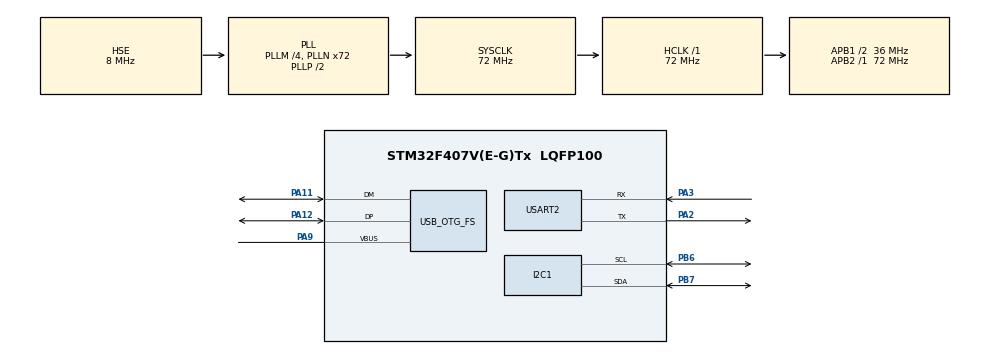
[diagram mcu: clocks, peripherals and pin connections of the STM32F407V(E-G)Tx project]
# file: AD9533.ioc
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Mcu.Family=STM32F4
Mcu.Name=STM32F407V(E-G)Tx
Mcu.Package=LQFP100
NVIC.I2C1_ER_IRQn=true\:2\:0\:true\:false\:true\:true\:true\:true
NVIC.I2C1_EV_IRQn=true\:2\:0\:true\:false\:true\:true\:true\:true
NVIC.OTG_FS_IRQn=true\:0\:0\:false\:false\:true\:false\:true\:true
NVIC.PriorityGroup=NVIC_PRIORITYGROUP_2
PA11.Mode=Device_Only
PA11.Signal=USB_OTG_FS_DM
PA12.Mode=Device_Only
PA12.Signal=USB_OTG_FS_DP
PA2.Mode=Asynchronous
PA2.Signal=USART2_TX
PA3.Mode=Asynchronous
PA3.Signal=USART2_RX
PA9.Mode=Activate_VBUS
PA9.Signal=USB_OTG_FS_VBUS
PB6.Mode=I2C
PB6.Signal=I2C1_SCL
PB7.Mode=I2C
PB7.Signal=I2C1_SDA
PH0-OSC_IN.Mode=HSE-External-Oscillator
PH0-OSC_IN.Signal=RCC_OSC_IN
PH1-OSC_OUT.Mode=HSE-External-Oscillator
PH1-OSC_OUT.Signal=RCC_OSC_OUT
ProjectManager.HeapSize=0x200
ProjectManager.StackSize=0x400
ProjectManager.TargetToolchain=STM32CubeIDE
RCC.48MHZClocksFreq_Value=48000000
RCC.AHBFreq_Value=72000000
RCC.APB1CLKDivider=RCC_HCLK_DIV2
RCC.APB1Freq_Value=36000000
RCC.APB1TimFreq_Value=72000000
RCC.APB2Freq_Value=72000000
RCC.APB2TimFreq_Value=72000000
RCC.CortexFreq_Value=72000000
RCC.HCLKFreq_Value=72000000
RCC.HSE_VALUE=8000000
RCC.HSI_VALUE=16000000
RCC.LSE_VALUE=32768
RCC.PLLM=4
RCC.PLLN=72
RCC.PLLQ=3
RCC.SYSCLKFreq_VALUE=72000000
RCC.SYSCLKSource=RCC_SYSCLKSOURCE_PLLCLK
RCC.VCOOutputFreq_Value=144000000
USART2.VirtualMode=VM_ASYNC
USB_DEVICE.CLASS_NAME_FS=CDC
USB_DEVICE.VirtualMode-CDC_FS=Cdc
USB_DEVICE.VirtualModeFS=Cdc_FS
USB_OTG_FS.VirtualMode=Device_Only
VP_USB_DEVICE_VS_USB_DEVICE_CDC_FS.Mode=CDC_FS
board=custom

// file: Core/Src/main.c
/* USER CODE BEGIN Header */
/**
  ******************************************************************************
  * @file           : main.c
  * @brief          : Main program body
  ******************************************************************************
  * @attention
  *
  * Copyright (c) 2022 STMicroelectronics.
  * All rights reserved.
  *
  * This software is licensed under terms that can be found in the LICENSE file
  * in the root directory of this software component.
  * If no LICENSE file comes with this software, it is provided AS-IS.
  *
  ******************************************************************************
  */
/* USER CODE END Header */
#include "main.h"
#include "usb_device.h"

/* USER CODE BEGIN Includes */
#include "usbd_cdc_if.h"
#include <string.h>
#include "AD5933.h"

/* USER CODE END Includes */

I2C_HandleTypeDef hi2c1;

UART_HandleTypeDef huart2;

void SystemClock_Config(void);
static void MX_GPIO_Init(void);
static void MX_I2C1_Init(void);
static void MX_USART2_UART_Init(void);
void dmsg(char *msg);

int main(void)
{
  /* USER CODE BEGIN 1 */
	ad5933_t dev1={0};
	float temp=0;
	char msg[100]={0};
	int16_t real=0, imag=0;
  /* USER CODE END 1 */

  /* MCU Configuration--------------------------------------------------------*/

  /* Reset of all peripherals, Initializes the Flash interface and the Systick. */
  HAL_Init();

  /* Configure the system clock */
  SystemClock_Config();

  /* Initialize all configured peripherals */
  MX_GPIO_Init();
  MX_I2C1_Init();
  MX_USART2_UART_Init();
  MX_USB_DEVICE_Init();
  /* USER CODE BEGIN 2 */

  ad5933_init(&dev1, &hi2c1, 16000000, AD5933_CONTROL_EXT_SYSCLK , AD5933_GAIN_X1, AD5933_RANGE_2000mVpp);
  ad5933_configSweep(&dev1, 30000, 10, 10);
  ad5933_setSettlingTime(&dev1, AD5933_SETTLING_X1, 15);
  ad5933_startSweep(&dev1);
  /* USER CODE END 2 */

  /* Infinite loop */
  while (1)
  {
//	  temp = ad5933_getTemperature(&dev1);
//	  memset(msg,0,sizeof(msg));
//	  sprintf(msg,"Temp: %.2f",temp);
//	  dmsg(msg);
//	  memset(msg,0,sizeof(msg));
//	  sprintf(msg,"start: %lx",ad5933_getReg(&dev1, AD5933_REG_FREQ_START, 3));
//	  dmsg(msg);
//	  memset(msg,0,sizeof(msg));
//	  sprintf(msg,"inc: %lx",ad5933_getReg(&dev1, AD5933_REG_FREQ_INC, 3));
//	  dmsg(msg);
//	  memset(msg,0,sizeof(msg));
//	  sprintf(msg,"num: %lx",ad5933_getReg(&dev1, AD5933_REG_INC_NUM, 2));
//	  dmsg(msg);
//	  memset(msg,0,sizeof(msg));
//	  sprintf(msg,"num: %lx",ad5933_getReg(&dev1,AD5933_REG_SETTLING_CYCLES, 2));
//	  dmsg(msg);

	  ad5933_repeatFreq(&dev1, &imag, &real);
	  memset(msg,0,sizeof(msg));
	  sprintf(msg,"%d %d", real, imag);
	  dmsg(msg);

	  HAL_Delay (10);
  }

}

void dmsg(char *msg)
{
	char *str = malloc(strlen(msg) + 3);
	strcpy(str, msg);
	strcat(str, "\r\n");
	CDC_Transmit_FS((uint8_t*)str, strlen(str));
}

void SystemClock_Config(void)
{
  RCC_OscInitTypeDef RCC_OscInitStruct = {0};
  RCC_ClkInitTypeDef RCC_ClkInitStruct = {0};

  /** Configure the main internal regulator output voltage
  */
  __HAL_RCC_PWR_CLK_ENABLE();
  __HAL_PWR_VOLTAGESCALING_CONFIG(PWR_REGULATOR_VOLTAGE_SCALE1);

  /** Initializes the RCC Oscillators according to the specified parameters
  * in the RCC_OscInitTypeDef structure.
  */
  RCC_OscInitStruct.OscillatorType = RCC_OSCILLATORTYPE_HSE;
  RCC_OscInitStruct.HSEState = RCC_HSE_ON;
  RCC_OscInitStruct.PLL.PLLState = RCC_PLL_ON;
  RCC_OscInitStruct.PLL.PLLSource = RCC_PLLSOURCE_HSE;
  RCC_OscInitStruct.PLL.PLLM = 4;
  RCC_OscInitStruct.PLL.PLLN = 72;
  RCC_OscInitStruct.PLL.PLLP = RCC_PLLP_DIV2;
  RCC_OscInitStruct.PLL.PLLQ = 3;
  if (HAL_RCC_OscConfig(&RCC_OscInitStruct) != HAL_OK)
  {
    Error_Handler();
  }

  /** Initializes the CPU, AHB and APB buses clocks
  */
  RCC_ClkInitStruct.ClockType = RCC_CLOCKTYPE_HCLK|RCC_CLOCKTYPE_SYSCLK
                              |RCC_CLOCKTYPE_PCLK1|RCC_CLOCKTYPE_PCLK2;
  RCC_ClkInitStruct.SYSCLKSource = RCC_SYSCLKSOURCE_PLLCLK;
  RCC_ClkInitStruct.AHBCLKDivider = RCC_SYSCLK_DIV1;
  RCC_ClkInitStruct.APB1CLKDivider = RCC_HCLK_DIV2;
  RCC_ClkInitStruct.APB2CLKDivider = RCC_HCLK_DIV1;

  if (HAL_RCC_ClockConfig(&RCC_ClkInitStruct, FLASH_LATENCY_2) != HAL_OK)
  {
    Error_Handler();
  }
}

static void MX_I2C1_Init(void)
{

  hi2c1.Instance = I2C1;
  hi2c1.Init.ClockSpeed = 100000;
  hi2c1.Init.DutyCycle = I2C_DUTYCYCLE_2;
  hi2c1.Init.OwnAddress1 = 0;
  hi2c1.Init.AddressingMode = I2C_ADDRESSINGMODE_7BIT;
  hi2c1.Init.DualAddressMode = I2C_DUALADDRESS_DISABLE;
  hi2c1.Init.OwnAddress2 = 0;
  hi2c1.Init.GeneralCallMode = I2C_GENERALCALL_DISABLE;
  hi2c1.Init.NoStretchMode = I2C_NOSTRETCH_DISABLE;
  if (HAL_I2C_Init(&hi2c1) != HAL_OK)
  {
    Error_Handler();
  }

}

static void MX_USART2_UART_Init(void)
{

  huart2.Instance = USART2;
  huart2.Init.BaudRate = 115200;
  huart2.Init.WordLength = UART_WORDLENGTH_8B;
  huart2.Init.StopBits = UART_STOPBITS_1;
  huart2.Init.Parity = UART_PARITY_NONE;
  huart2.Init.Mode = UART_MODE_TX_RX;
  huart2.Init.HwFlowCtl = UART_HWCONTROL_NONE;
  huart2.Init.OverSampling = UART_OVERSAMPLING_16;
  if (HAL_UART_Init(&huart2) != HAL_OK)
  {
    Error_Handler();
  }

}

static void MX_GPIO_Init(void)
{

  /* GPIO Ports Clock Enable */
  __HAL_RCC_GPIOH_CLK_ENABLE();
  __HAL_RCC_GPIOA_CLK_ENABLE();
  __HAL_RCC_GPIOB_CLK_ENABLE();

}

void Error_Handler(void)
{
  __disable_irq();
  while (1)
  {
  }
}
